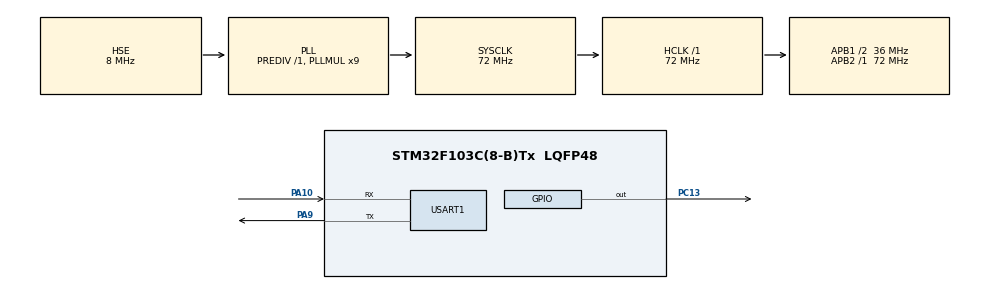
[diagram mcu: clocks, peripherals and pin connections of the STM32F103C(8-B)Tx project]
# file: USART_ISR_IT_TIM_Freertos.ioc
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FREERTOS.Queues01=LED_Queue,16,uint8_t,0,Dynamic,NULL,NULL
FREERTOS.Tasks01=LED_UART_Task,24,128,Start_LED_UART_Task,Default,NULL,Dynamic,NULL,NULL
Mcu.Family=STM32F1
Mcu.Name=STM32F103C(8-B)Tx
Mcu.Package=LQFP48
NVIC.PriorityGroup=NVIC_PRIORITYGROUP_4
NVIC.TIM2_IRQn=true\:5\:0\:false\:false\:true\:true\:true\:true\:true
NVIC.TIM4_IRQn=true\:15\:0\:false\:false\:true\:false\:false\:true\:true
NVIC.TimeBase=TIM4_IRQn
NVIC.TimeBaseIP=TIM4
NVIC.USART1_IRQn=true\:5\:0\:false\:false\:true\:true\:true\:true\:true
PA10.Mode=Asynchronous
PA10.Signal=USART1_RX
PA13.Mode=Serial_Wire
PA13.Signal=SYS_JTMS-SWDIO
PA14.Mode=Serial_Wire
PA14.Signal=SYS_JTCK-SWCLK
PA9.Mode=Asynchronous
PA9.Signal=USART1_TX
PC13-TAMPER-RTC.PinState=GPIO_PIN_SET
PC13-TAMPER-RTC.Signal=GPIO_Output
PD0-OSC_IN.Mode=HSE-External-Oscillator
PD0-OSC_IN.Signal=RCC_OSC_IN
PD1-OSC_OUT.Mode=HSE-External-Oscillator
PD1-OSC_OUT.Signal=RCC_OSC_OUT
ProjectManager.HeapSize=0x200
ProjectManager.StackSize=0x400
ProjectManager.TargetToolchain=MDK-ARM V5.32
RCC.AHBFreq_Value=72000000
RCC.APB1CLKDivider=RCC_HCLK_DIV2
RCC.APB1Freq_Value=36000000
RCC.APB1TimFreq_Value=72000000
RCC.APB2Freq_Value=72000000
RCC.APB2TimFreq_Value=72000000
RCC.EnbaleCSS=true
RCC.HCLKFreq_Value=72000000
RCC.PLLMUL=RCC_PLL_MUL9
RCC.PLLSourceVirtual=RCC_PLLSOURCE_HSE
RCC.SYSCLKFreq_VALUE=72000000
RCC.SYSCLKSource=RCC_SYSCLKSOURCE_PLLCLK
RCC.USBFreq_Value=72000000
TIM2.Period=10000-1
TIM2.Prescaler=7200-1
USART1.VirtualMode=VM_ASYNC
VP_FREERTOS_VS_CMSIS_V2.Mode=CMSIS_V2
VP_SYS_VS_tim4.Mode=TIM4
VP_TIM2_VS_ClockSourceINT.Mode=Internal
board=custom

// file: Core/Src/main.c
/* USER CODE BEGIN Header */
/**
  ******************************************************************************
  * @file           : main.c
  * @brief          : Main program body
  ******************************************************************************
  * @attention
  *
  * Copyright (c) 2025 STMicroelectronics.
  * All rights reserved.
  *
  * This software is licensed under terms that can be found in the LICENSE file
  * in the root directory of this software component.
  * If no LICENSE file comes with this software, it is provided AS-IS.
  *
  ******************************************************************************
  */
/* USER CODE END Header */
#include "main.h"
#include "cmsis_os.h"
#include "tim.h"
#include "usart.h"
#include "gpio.h"

/* USER CODE BEGIN Includes */

#include "cmsis_os2.h"
extern osMessageQueueId_t LED_QueueHandle;

/* USER CODE END Includes */

void SystemClock_Config(void);
void MX_FREERTOS_Init(void);

int main(void)
{

  /* MCU Configuration--------------------------------------------------------*/

  /* Reset of all peripherals, Initializes the Flash interface and the Systick. */
  HAL_Init();

  /* Configure the system clock */
  SystemClock_Config();

  /* Initialize all configured peripherals */
  MX_GPIO_Init();
  MX_TIM2_Init();
  MX_USART1_UART_Init();
  /* USER CODE BEGIN 2 */

  HAL_TIM_Base_Start_IT(&htim2);

  /* USER CODE END 2 */

  /* Init scheduler */
  osKernelInitialize();

  /* Call init function for freertos objects (in cmsis_os2.c) */
  MX_FREERTOS_Init();

  /* Start scheduler */
  osKernelStart();

  /* We should never get here as control is now taken by the scheduler */

  /* Infinite loop */
  while (1)
  {

  }
}

void SystemClock_Config(void)
{
  RCC_OscInitTypeDef RCC_OscInitStruct = {0};
  RCC_ClkInitTypeDef RCC_ClkInitStruct = {0};

  /** Initializes the RCC Oscillators according to the specified parameters
  * in the RCC_OscInitTypeDef structure.
  */
  RCC_OscInitStruct.OscillatorType = RCC_OSCILLATORTYPE_HSE;
  RCC_OscInitStruct.HSEState = RCC_HSE_ON;
  RCC_OscInitStruct.HSEPredivValue = RCC_HSE_PREDIV_DIV1;
  RCC_OscInitStruct.HSIState = RCC_HSI_ON;
  RCC_OscInitStruct.PLL.PLLState = RCC_PLL_ON;
  RCC_OscInitStruct.PLL.PLLSource = RCC_PLLSOURCE_HSE;
  RCC_OscInitStruct.PLL.PLLMUL = RCC_PLL_MUL9;
  if (HAL_RCC_OscConfig(&RCC_OscInitStruct) != HAL_OK)
  {
    Error_Handler();
  }

  /** Initializes the CPU, AHB and APB buses clocks
  */
  RCC_ClkInitStruct.ClockType = RCC_CLOCKTYPE_HCLK|RCC_CLOCKTYPE_SYSCLK
                              |RCC_CLOCKTYPE_PCLK1|RCC_CLOCKTYPE_PCLK2;
  RCC_ClkInitStruct.SYSCLKSource = RCC_SYSCLKSOURCE_PLLCLK;
  RCC_ClkInitStruct.AHBCLKDivider = RCC_SYSCLK_DIV1;
  RCC_ClkInitStruct.APB1CLKDivider = RCC_HCLK_DIV2;
  RCC_ClkInitStruct.APB2CLKDivider = RCC_HCLK_DIV1;

  if (HAL_RCC_ClockConfig(&RCC_ClkInitStruct, FLASH_LATENCY_2) != HAL_OK)
  {
    Error_Handler();
  }

  /** Enables the Clock Security System
  */
  HAL_RCC_EnableCSS();
}

void HAL_TIM_PeriodElapsedCallback(TIM_HandleTypeDef *htim)
{
  if (htim->Instance == TIM4)
  {
    HAL_IncTick();
  }
  /* USER CODE BEGIN Callback 1 */

  if (htim->Instance == TIM2)
  {
    uint8_t event = 1;
    osMessageQueuePut(LED_QueueHandle, &event, 0, 0);
  }

  /* USER CODE END Callback 1 */
}

void Error_Handler(void)
{
  __disable_irq();
  while (1)
  {
  }
}

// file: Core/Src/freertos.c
/* USER CODE BEGIN Header */
/**
  ******************************************************************************
  * File Name          : freertos.c
  * Description        : Code for freertos applications
  ******************************************************************************
  * @attention
  *
  * Copyright (c) 2025 STMicroelectronics.
  * All rights reserved.
  *
  * This software is licensed under terms that can be found in the LICENSE file
  * in the root directory of this software component.
  * If no LICENSE file comes with this software, it is provided AS-IS.
  *
  ******************************************************************************
  */
/* USER CODE END Header */

#include "FreeRTOS.h"
#include "task.h"
#include "main.h"
#include "cmsis_os.h"

/* USER CODE BEGIN Includes */

#include "queue.h"
#include "usart.h"
#include "string.h"

// extern QueueHandle_t LED_Queue;

/* USER CODE END Includes */

/* Definitions for LED_UART_Task */
osThreadId_t LED_UART_TaskHandle;
const osThreadAttr_t LED_UART_Task_attributes = {
  .name = "LED_UART_Task",
  .stack_size = 128 * 4,
  .priority = (osPriority_t) osPriorityNormal,
};
/* Definitions for LED_Queue */
osMessageQueueId_t LED_QueueHandle;
const osMessageQueueAttr_t LED_Queue_attributes = {
  .name = "LED_Queue"
};

void Start_LED_UART_Task(void *argument);

void MX_FREERTOS_Init(void); /* (MISRA C 2004 rule 8.1) */

void MX_FREERTOS_Init(void) {

  /* Create the queue(s) */
  /* creation of LED_Queue */
  LED_QueueHandle = osMessageQueueNew (16, sizeof(uint8_t), &LED_Queue_attributes);

  /* Create the thread(s) */
  /* creation of LED_UART_Task */
  LED_UART_TaskHandle = osThreadNew(Start_LED_UART_Task, NULL, &LED_UART_Task_attributes);

}

void Start_LED_UART_Task(void *argument)
{
  /* USER CODE BEGIN Start_LED_UART_Task */

  uint8_t event;
  uint8_t led_state = 0;
  const char *msg = "LED toggled!\r\n";

  /* Infinite loop */
  for(;;)
  {
    if (osMessageQueueGet(LED_QueueHandle, &event, NULL, osWaitForever) == osOK)
    {
      if (event == 1)
      {
        led_state = !led_state;
        HAL_GPIO_WritePin(GPIOC, GPIO_PIN_13,
                          led_state ? GPIO_PIN_RESET : GPIO_PIN_SET);

        // Send a message over UART
        HAL_UART_Transmit(&huart1, (uint8_t*)msg, strlen(msg), HAL_MAX_DELAY);
      }
    }
    osDelay(1);
  }
  /* USER CODE END Start_LED_UART_Task */
}
